# S6E1A1xB register map
Vendor: Cypress; File version: 2.1
CPU: CM0PLUS r0p1, little endian, no MPU, no FPU, 2 interrupt priority bits
Registers are 32-bit, read-write, reset 0x0 unless marked. A register's access mark holds for its fields unless they carry their own. Offsets are from the block's base; [hi:lo] are bit positions.

## INTREQ — Interrupts
Base 0x40031000
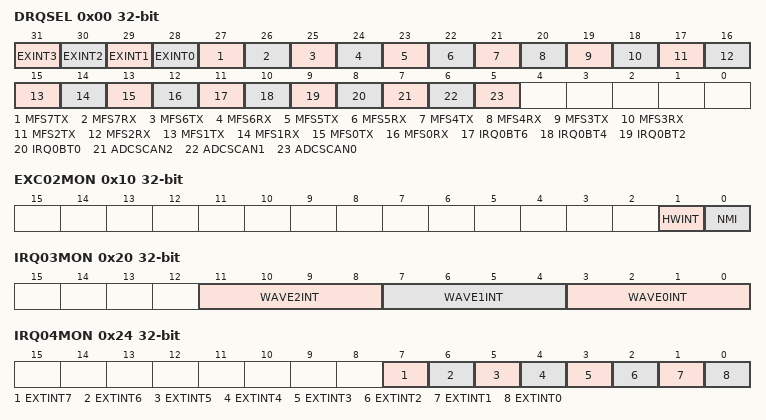
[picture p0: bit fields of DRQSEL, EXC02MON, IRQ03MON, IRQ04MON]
0x00 DRQSEL — DMA Request Selection Register [BHW]
  [31] EXINT3 — External pin interrupt ch.3
  [30] EXINT2 — External pin interrupt ch.2
  [29] EXINT1 — External pin interrupt ch.1
  [28] EXINT0 — External pin interrupt ch.0
  [27] MFS7TX — MFS ch.7 transmission interrupt
  [26] MFS7RX — MFS ch.7 reception interrupt
  [25] MFS6TX — MFS ch.6 transmission interrupt
  [24] MFS6RX — MFS ch.6 reception interrupt
  [23] MFS5TX — MFS ch.5 transmission interrupt
  [22] MFS5RX — MFS ch.5 reception interrupt
  [21] MFS4TX — MFS ch.4 transmission interrupt
  [20] MFS4RX — MFS ch.4 reception interrupt
  [19] MFS3TX — MFS ch.3 transmission interrupt
  [18] MFS3RX — MFS ch.3 reception interrupt
  [17] MFS2TX — MFS ch.2 transmission interrupt
  [16] MFS2RX — MFS ch.2 reception interrupt
  [15] MFS1TX — MFS ch.1 transmission interrupt
  [14] MFS1RX — MFS ch.1 reception interrupt
  [13] MFS0TX — MFS ch.0 transmission interrupt
  [12] MFS0RX — MFS ch.0 reception interrupt
  [11] IRQ0BT6 — Base timer ch.6 source 0 (IRQ0) interrupt
  [10] IRQ0BT4 — Base timer ch.4 source 0 (IRQ0) interrupt
  [9] IRQ0BT2 — Base timer ch.2 source 0 (IRQ0) interrupt
  [8] IRQ0BT0 — Base timer ch.6 source 0 (IRQ0) interrupt
  [7] ADCSCAN2 — A/D converter unit 2 scan conversion interrupt
  [6] ADCSCAN1 — A/D converter unit 1 scan conversion interrupt
  [5] ADCSCAN0 — A/D converter unit 0 scan conversion interrupt
0x0C IRQCMODE — Interrupt Factor Vector Relocate Setting Register [BHW]
  [0] IRQCMODE — Select an interrupt factor vector. See periheral manual for details
0x10 EXC02MON ro — EXC02 Batch Read Register [BHW]
  [1] HWINT — Hardware watchdog timer interrupt request
  [0] NMI — NMIX external pin interrupt request
0x14 IRQ00MON ro — IRQ00 Batch Read Register [BHW]
  [0] FCSINT — Anomalous frequency detection by CSV interrupt request
0x18 IRQ01MON ro — IRQ01 Batch Read Register [BHW]
  [0] SWWDTINT — Software watchdog timer interrupt request
0x1C IRQ02MON ro — IRQ02 Batch Read Register [BHW]
  [0] LVDINT — Low voltage detection (LVD) interrupt request
0x20 IRQ03MON ro — IRQ03 Batch Read Register [BHW]
  [11:8] WAVE2INT — WFG timer 54 interrupt request in MFT unit 2
  [7:4] WAVE1INT — WFG timer 54 interrupt request in MFT unit 1
  [3:0] WAVE0INT — DTIF (motor emergency stop) interrupt request in MFT unit 0
0x24 IRQ04MON ro — IRQ04 Batch Read Register [BHW]
  [7] EXTINT7 — Interrupt request of external interrupt ch.7
  [6] EXTINT6 — Interrupt request of external interrupt ch.6
  [5] EXTINT5 — Interrupt request of external interrupt ch.5
  [4] EXTINT4 — Interrupt request of external interrupt ch.4
  [3] EXTINT3 — Interrupt request of external interrupt ch.3
  [2] EXTINT2 — Interrupt request of external interrupt ch.2
  [1] EXTINT1 — Interrupt request of external interrupt ch.1
  [0] EXTINT0 — Interrupt request of external interrupt ch.0
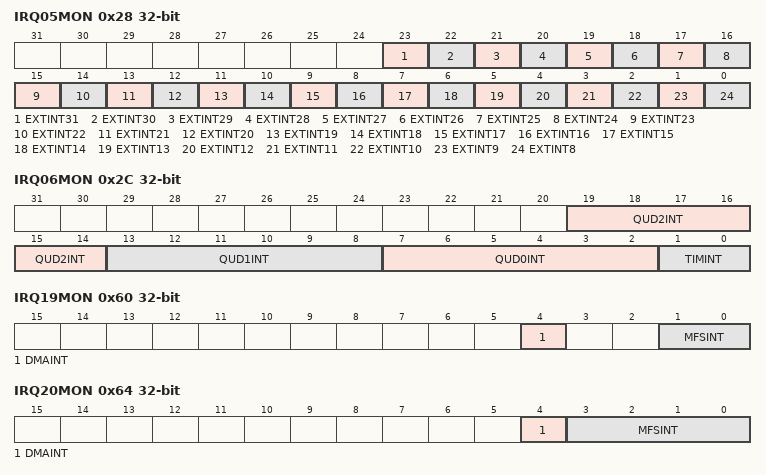
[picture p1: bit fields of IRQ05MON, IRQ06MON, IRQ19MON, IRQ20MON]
0x28 IRQ05MON ro — IRQ05 Batch Read Register [BHW]
  [23] EXTINT31 — Interrupt request of external interrupt ch.31
  [22] EXTINT30 — Interrupt request of external interrupt ch.30
  [21] EXTINT29 — Interrupt request of external interrupt ch.29
  [20] EXTINT28 — Interrupt request of external interrupt ch.28
  [19] EXTINT27 — Interrupt request of external interrupt ch.27
  [18] EXTINT26 — Interrupt request of external interrupt ch.26
  [17] EXTINT25 — Interrupt request of external interrupt ch.25
  [16] EXTINT24 — Interrupt request of external interrupt ch.24
  [15] EXTINT23 — Interrupt request of external interrupt ch.23
  [14] EXTINT22 — Interrupt request of external interrupt ch.22
  [13] EXTINT21 — Interrupt request of external interrupt ch.21
  [12] EXTINT20 — Interrupt request of external interrupt ch.20
  [11] EXTINT19 — Interrupt request of external interrupt ch.19
  [10] EXTINT18 — Interrupt request of external interrupt ch.18
  [9] EXTINT17 — Interrupt request of external interrupt ch.17
  [8] EXTINT16 — Interrupt request of external interrupt ch.16
  [7] EXTINT15 — Interrupt request of external interrupt ch.15
  [6] EXTINT14 — Interrupt request of external interrupt ch.14
  [5] EXTINT13 — Interrupt request of external interrupt ch.13
  [4] EXTINT12 — Interrupt request of external interrupt ch.12
  [3] EXTINT11 — Interrupt request of external interrupt ch.11
  [2] EXTINT10 — Interrupt request of external interrupt ch.10
  [1] EXTINT9 — Interrupt request of external interrupt ch.9
  [0] EXTINT8 — Interrupt request of external interrupt ch.8
0x2C IRQ06MON ro — IRQ06 Batch Read Register [BHW]
  [19:14] QUD2INT — Interrupt requests of the QPRC ch.2
  [13:8] QUD1INT — Interrupt requests of the QPRC ch.1
  [7:2] QUD0INT — Interrupt requests of the QPRC ch.0
  [1:0] TIMINT — Dual timer interrupt request
0x30 IRQ07MON ro — IRQ07 Batch Read Register [BHW]
  [1:0] MFSINT — Reception interrupt requests of MFS ch 0/8
0x34 IRQ08MON ro — IRQ08 Batch Read Register [BHW]
  [3:0] MFSINT — Status/Transmission interrupt requests of MFS ch 0/8
0x38 IRQ09MON ro — IRQ09 Batch Read Register [BHW]
  [1:0] MFSINT — Reception interrupt requests of MFS ch 1/9
0x3C IRQ10MON ro — IRQ10 Batch Read Register [BHW]
  [3:0] MFSINT — Status/Transmission interrupt requests of MFS ch 1/9
0x40 IRQ11MON ro — IRQ11 Batch Read Register [BHW]
  [1:0] MFSINT — Reception interrupt requests of MFS ch 2/10
0x44 IRQ12MON ro — IRQ12 Batch Read Register [BHW]
  [3:0] MFSINT — Status/Transmission interrupt requests of MFS ch 2/10
0x48 IRQ13MON ro — IRQ13 Batch Read Register [BHW]
  [1:0] MFSINT — Reception interrupt requests of MFS ch 3/11
0x4C IRQ14MON ro — IRQ14 Batch Read Register [BHW]
  [3:0] MFSINT — Status/Transmission interrupt requests of MFS ch 3/11
0x50 IRQ15MON ro — IRQ15 Batch Read Register [BHW]
  [1:0] MFSINT — Reception interrupt requests of MFS ch 4/12
0x54 IRQ16MON ro — IRQ16 Batch Read Register [BHW]
  [3:0] MFSINT — Status/Transmission interrupt requests of MFS ch 4/12
0x58 IRQ17MON ro — IRQ17 Batch Read Register [BHW]
  [1:0] MFSINT — Reception interrupt requests of MFS ch 5/13
0x5C IRQ18MON ro — IRQ18 Batch Read Register [BHW]
  [3:0] MFSINT — Status/Transmission interrupt requests of MFS ch 5/13
0x60 IRQ19MON ro — IRQ19 Batch Read Register [BHW]
  [4] DMAINT — Interrupt request of DMAC ch.0
  [1:0] MFSINT — Reception interrupt requests of MFS ch 6/14
0x64 IRQ20MON ro — IRQ20 Batch Read Register [BHW]
  [4] DMAINT — Interrupt request of DMAC ch.1
  [3:0] MFSINT — Status/Transmission interrupt requests of MFS ch 6/14
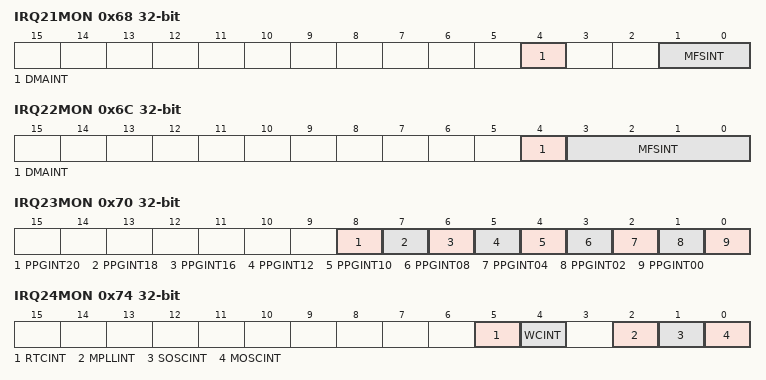
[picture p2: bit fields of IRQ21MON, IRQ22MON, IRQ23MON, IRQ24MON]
0x68 IRQ21MON ro — IRQ21 Batch Read Register [BHW]
  [4] DMAINT — Interrupt request of DMAC ch.2
  [1:0] MFSINT — Reception interrupt requests of MFS ch 7/15
0x6C IRQ22MON ro — IRQ22 Batch Read Register [BHW]
  [4] DMAINT — Interrupt request of DMAC ch.3
  [3:0] MFSINT — Status/Transmission interrupt requests of MFS ch 7/15
0x70 IRQ23MON ro — IRQ23 Batch Read Register [BHW]
  [8] PPGINT20 — Interrupt request of PPG ch.20
  [7] PPGINT18 — Interrupt request of PPG ch.18
  [6] PPGINT16 — Interrupt request of PPG ch.16
  [5] PPGINT12 — Interrupt request of PPG ch.12
  [4] PPGINT10 — Interrupt request of PPG ch.10
  [3] PPGINT08 — Interrupt request of PPG ch.8
  [2] PPGINT04 — Interrupt request of PPG ch.4
  [1] PPGINT02 — Interrupt request of PPG ch.2
  [0] PPGINT00 — Interrupt request of PPG ch.0
0x74 IRQ24MON ro — IRQ24 Batch Read Register [BHW]
  [5] RTCINT — RTC interrupt request
  [4] WCINT — Watch counter interrupt request
  [2] MPLLINT — Stabilization wait completion interrupt request for main PLL oscillation
  [1] SOSCINT — Stabilization wait completion interrupt request for sub-clock oscillation
  [0] MOSCINT — Stabilization wait completion interrupt request for main clock oscillation
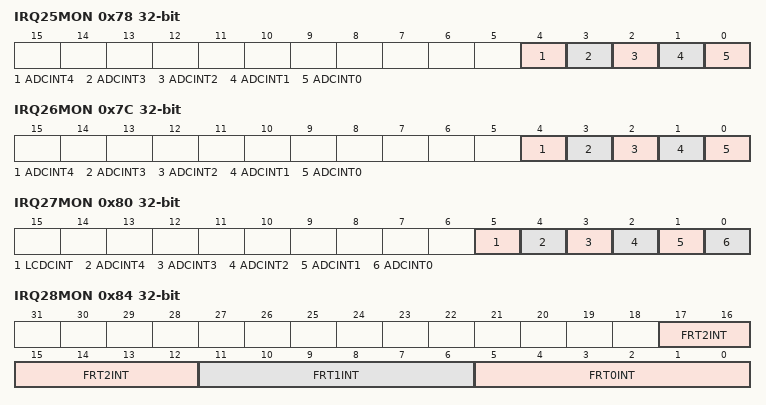
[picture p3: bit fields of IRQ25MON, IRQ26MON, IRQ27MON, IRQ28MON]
0x78 IRQ25MON ro — IRQ25 Batch Read Register [BHW]
  [4] ADCINT4 — Range comparison result interrupt request in the A/D converter unit 0
  [3] ADCINT3 — Conversion result comparison interrupt request in the A/D converter unit 0
  [2] ADCINT2 — FIFO overrun interrupt request in the A/D converter unit 0
  [1] ADCINT1 — Scan conversion interrupt request in the A/D converter unit 0
  [0] ADCINT0 — Priority conversion interrupt request in the A/D converter unit 0
0x7C IRQ26MON ro — IRQ26 Batch Read Register [BHW]
  [4] ADCINT4 — Range comparison result interrupt request in the A/D converter unit 1
  [3] ADCINT3 — Conversion result comparison interrupt request in the A/D converter unit 1
  [2] ADCINT2 — FIFO overrun interrupt request in the A/D converter unit 1
  [1] ADCINT1 — Scan conversion interrupt request in the A/D converter unit 1
  [0] ADCINT0 — Priority conversion interrupt request in the A/D converter unit 1
0x80 IRQ27MON ro — IRQ27 Batch Read Register [BHW]
  [5] LCDCINT — Interrupt request for LCD controller
  [4] ADCINT4 — Range comparison result interrupt request in the A/D converter unit 2
  [3] ADCINT3 — Conversion result comparison interrupt request in the A/D converter unit 2
  [2] ADCINT2 — FIFO overrun interrupt request in the A/D converter unit 2
  [1] ADCINT1 — Scan conversion interrupt request in the A/D converter unit 2
  [0] ADCINT0 — Priority conversion interrupt request in the A/D converter unit 2
0x84 IRQ28MON ro — IRQ28 Batch Read Register [BHW]
  [17:12] FRT2INT — Zero/Peak detection interrupt request of the free run timers in the MFT unit 2
  [11:6] FRT1INT — Zero/Peak detection interrupt request of the free run timers in the MFT unit 1
  [5:0] FRT0INT — Zero/Peak detection interrupt request of the free run timers in the MFT unit 0
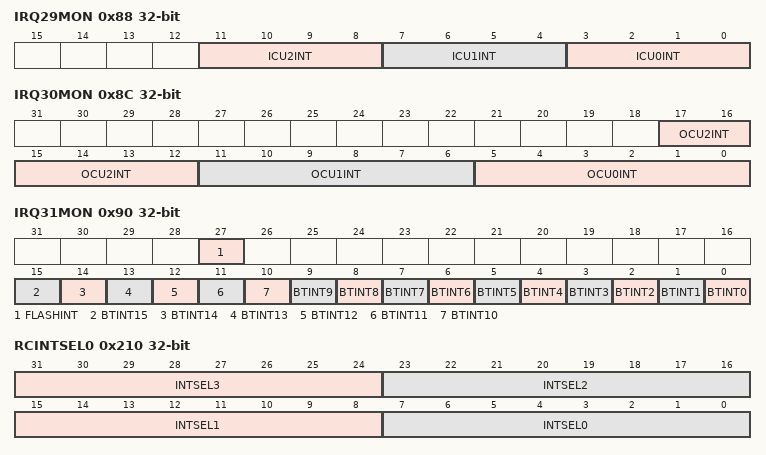
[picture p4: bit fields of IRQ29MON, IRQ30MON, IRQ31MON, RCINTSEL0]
0x88 IRQ29MON ro — IRQ29 Batch Read Register [BHW]
  [11:8] ICU2INT — Interrupt request of the input capture in the MFT unit 2
  [7:4] ICU1INT — Interrupt request of the input capture in the MFT unit 1
  [3:0] ICU0INT — Interrupt request of the input capture in the MFT unit 0
0x8C IRQ30MON ro — IRQ30 Batch Read Register [BHW]
  [17:12] OCU2INT — Interrupt request of the output compare in the MFT unit 2
  [11:6] OCU1INT — Interrupt request of the output compare in the MFT unit 1
  [5:0] OCU0INT — Interrupt request of the output compare in the MFT unit 0
0x90 IRQ31MON ro — IRQ31 Batch Read Register [BHW]
  [27] FLASHINT — RDY/HANG interrupt request for f lash memory
  [15] BTINT15 — IRQ1 interrupt request of the base timer ch.7
  [14] BTINT14 — IRQ0 interrupt request of the base timer ch.7
  [13] BTINT13 — IRQ1 interrupt request of the base timer ch.6
  [12] BTINT12 — IRQ0 interrupt request of the base timer ch.6
  [11] BTINT11 — IRQ1 interrupt request of the base timer ch.5
  [10] BTINT10 — IRQ0 interrupt request of the base timer ch.5
  [9] BTINT9 — IRQ1 interrupt request of the base timer ch.4
  [8] BTINT8 — IRQ0 interrupt request of the base timer ch.4
  [7] BTINT7 — IRQ1 interrupt request of the base timer ch.3
  [6] BTINT6 — IRQ0 interrupt request of the base timer ch.3
  [5] BTINT5 — IRQ1 interrupt request of the base timer ch.2
  [4] BTINT4 — IRQ0 interrupt request of the base timer ch.2
  [3] BTINT3 — IRQ1 interrupt request of the base timer ch.1
  [2] BTINT2 — IRQ0 interrupt request of the base timer ch.1
  [1] BTINT1 — IRQ1 interrupt request of the base timer ch.0
  [0] BTINT0 — IRQ0 interrupt request of the base timer ch.0
0x210 RCINTSEL0 — Interrupt Factor Selection Register 0 [BHW]
  [31:24] INTSEL3 — Select the interrupt factor for the interrupt vector No.22
  [23:16] INTSEL2 — Select the interrupt factor for the interrupt vector No.21
  [15:8] INTSEL1 — Select the interrupt factor for the interrupt vector No.20
  [7:0] INTSEL0 — Select the interrupt factor for the interrupt vector No.19
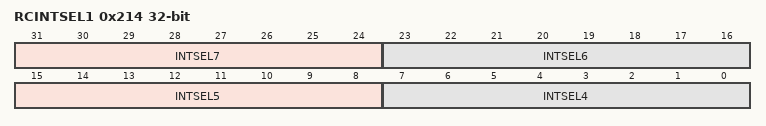
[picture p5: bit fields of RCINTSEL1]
0x214 RCINTSEL1 — Interrupt Factor Selection Register 1 [BHW]
  [31:24] INTSEL7 — Select the interrupt factor for the interrupt vector No.26
  [23:16] INTSEL6 — Select the interrupt factor for the interrupt vector No.25
  [15:8] INTSEL5 — Select the interrupt factor for the interrupt vector No.24
  [7:0] INTSEL4 — Select the interrupt factor for the interrupt vector No.23
